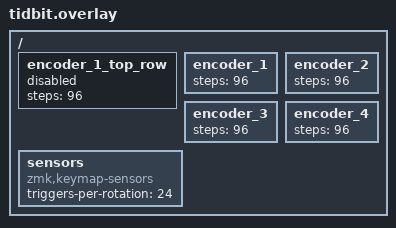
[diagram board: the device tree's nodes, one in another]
/ {

    encoder_1_top_row: encoder_1_top_row {
        steps = <96>;
        status = "disabled";
    };

    encoder_1: encoder_1 {
        steps = <96>;
    };

    /* dentless encoder */
    encoder_2: encoder_2 {
        steps = <96>;
    };

    /* dentless encoder */
    encoder_3: encoder_3 {
        steps = <96>;
    };

    encoder_4: encoder_4 {
        steps = <96>;
    };

    sensors: sensors {
	compatible = "zmk,keymap-sensors";
        triggers-per-rotation = <24>;
    };
};
